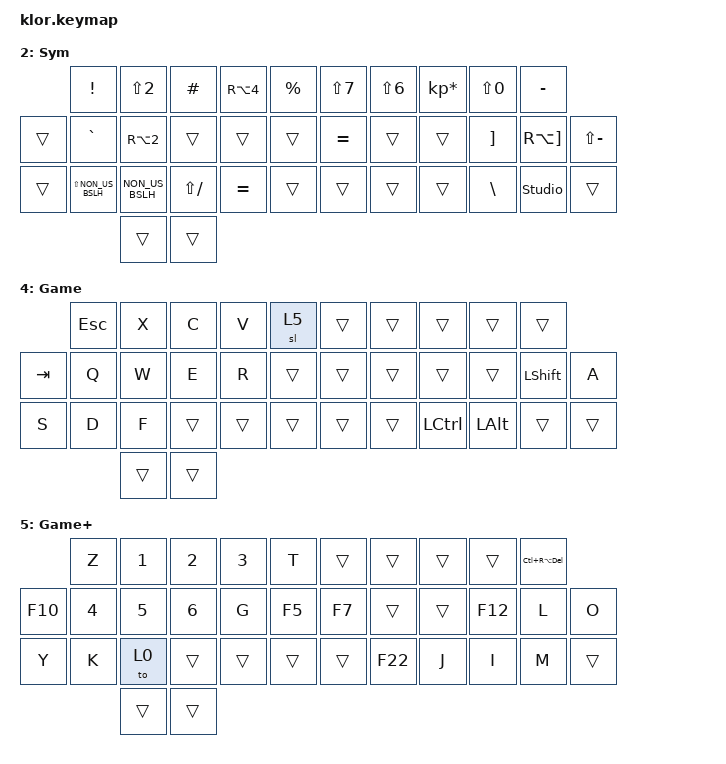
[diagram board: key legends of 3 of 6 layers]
#include <behaviors.dtsi>
#include <dt-bindings/zmk/keys.h>

#define Base        0
#define Nav         1
#define Sym         2
#define Fun         3
#define Game        4
#define Gameplus    5

&mt {
    quick-tap-ms = <100>;
    global-quick-tap;
    flavor = "tap-preferred";
    tapping-term-ms = <170>;
};

&lt {
    tapping-term-ms = <240>;
    flavor = "balanced";
    quick-tap-ms = <150>;
};

/ {
    behaviors {
        hm: homerow_mods {
            compatible = "zmk,behavior-hold-tap";
            label = "HOMEROW_MODS";
            #binding-cells = <2>;
            flavor = "tap-preferred";
            tapping-term-ms = <200>;
            quick-tap-ms = <125>;
            global-quick-tap;
            bindings = <&kp>, <&kp>;
        };
    };

    combos { compatible = "zmk,combos"; };

    keymap {
        compatible = "zmk,keymap";

        Base {
            display-name = "Base";
            bindings = <
             &kp Q       &kp W          &kp E         &kp R         &kp T  &kp Y  &kp U        &kp I        &kp O       &kp P
&lt 1 ESC    &hm LGUI A  &hm LALT S     &hm LCTRL D   &hm LSHIFT F  &kp G  &kp H  &hm RSHFT J  &hm RCTRL K  &hm RALT L  &hm RGUI SEMICOLON  &kp LEFT_BRACKET
&lt 2 LCTRL  &lt 3 Z     &kp X          &kp C         &kp V         &kp B  &kp N  &kp M        &kp COMMA    &kp DOT     &kp SLASH           &kp SINGLE_QUOTE
                         &mt LCTRL DEL  &lt 1 ESCAPE  &kp SPACE                   &kp RET      &kp BSPC     &kp MINUS
            >;

            sensor-bindings =
                <&inc_dec_kp RIGHT LEFT>,
                <&inc_dec_kp UP_ARROW DOWN_ARROW>;
        };

        Nav {
            display-name = "Nav";
            bindings = <
                &kp TILDE  &kp LS(TAB)  &trans     &kp TAB        &kp RA(NUMBER_7)  &kp RA(NUMBER_0)  &kp NUMBER_7  &kp NUMBER_8  &kp NUMBER_9  &kp NUMBER_0
&kp LEFT_SHIFT  &kp LEFT   &kp UP       &kp RIGHT  &kp PG_UP      &kp RA(NUMBER_8)  &kp RA(NUMBER_9)  &kp NUMBER_4  &kp NUMBER_5  &kp NUMBER_6  &kp MINUS          &kp SLASH
&trans          &kp HOME   &kp DOWN     &kp END    &kp PAGE_DOWN  &kp LS(NUMBER_8)  &kp LS(NUMBER_9)  &kp NUMBER_1  &kp NUMBER_2  &kp NUMBER_3  &kp LS(BACKSLASH)  &kp LS(NUMBER_7)
                           &trans       &kp DOT    &trans                                             &trans        &trans        &trans
            >;
        };

        Sym {
            display-name = "Sym";
            bindings = <
        &kp EXCL             &kp LS(NUMBER_2)  &kp HASH       &kp RA(NUMBER_4)  &kp PERCENT  &kp LS(NUMBER_7)  &kp LS(NUMBER_6)  &kp KP_ASTERISK  &kp LS(NUMBER_0)   &kp MINUS
&trans  &kp GRAVE            &kp RA(NUMBER_2)  &trans         &trans            &trans       &kp EQUAL         &trans            &trans           &kp RIGHT_BRACKET  &kp RA(RIGHT_BRACKET)  &kp LS(MINUS)
&trans  &kp LS(NON_US_BSLH)  &kp NON_US_BSLH   &kp LS(SLASH)  &kp EQUAL         &trans       &trans            &trans            &trans           &kp BACKSLASH      &studio_unlock     &trans
                             &trans            &trans
            >;
        };

        Fun {
            display-name = "Fun";
            bindings = <
        &kp F1       &kp F2  &kp F3  &kp F4  &kp F5  &kp F6  &kp F7                      &kp F10                      &kp F11  &kp F12
&trans  &trans       &trans  &trans  &trans  &trans  &trans  &kp LC(LA(LEFT_ARROW))      &kp LA(LC(RIGHT_ARROW))      &trans   &trans   &trans
&trans  &bootloader  &trans  &trans  &trans  &trans  &trans  &kp LS(LA(LC(LEFT_ARROW)))  &kp LA(LS(LC(RIGHT_ARROW)))  &trans   &trans   &studio_unlock
                     &trans  &trans  &trans                  &trans                      &trans                       &trans
            >;
        };

        Gaming {
            display-name = "Game";
            bindings = <
         &kp ESCAPE  &kp X   &kp C   &kp V   &sl 5   &trans  &trans  &trans     &trans        &trans
&kp TAB  &kp Q       &kp W   &kp E   &kp R   &trans  &trans  &trans  &trans     &trans        &kp LEFT_SHIFT  &kp A
&kp S    &kp D       &kp F   &trans  &trans  &trans  &trans  &trans  &kp LCTRL  &kp LEFT_ALT  &trans          &trans
                     &trans  &trans
            >;
        };

        Gaming+ {
            display-name = "Game+";
            bindings = <
         &kp Z         &kp NUMBER_1  &kp NUMBER_2  &kp NUMBER_3  &kp T   &trans  &trans   &trans  &trans   &kp LC(RA(DEL))
&kp F10  &kp NUMBER_4  &kp NUMBER_5  &kp NUMBER_6  &kp G         &kp F5  &kp F7  &trans   &trans  &kp F12  &kp L            &kp O
&kp Y    &kp K         &to 0         &trans        &trans        &trans  &trans  &kp F22  &kp J   &kp I    &kp M            &trans
                       &trans        &trans
            >;
        };
    };
};
